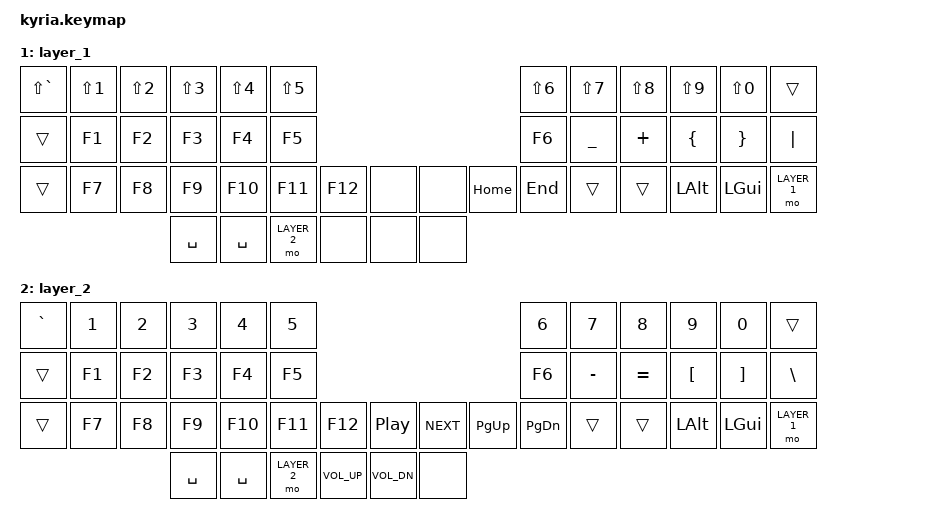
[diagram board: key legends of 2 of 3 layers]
/*
 * Copyright (c) 2020 The ZMK Contributors
 *
 * SPDX-License-Identifier: MIT
 */

#include <behaviors.dtsi>
#include <dt-bindings/zmk/keys.h>

// Layers

#define DEFAULT 0
#define LAYER_1 1
#define LAYER_2 2

/ {
    keymap {
        compatible = "zmk,keymap";

        default_layer {
            // ---------------------------------------------------------------------------------------------------------------------------------
            // |  TAB  |  Q  |  W  |  E   |  R   |  T   |                                              |  Y   |  U    |  I    |  O   |   P   | BSPC |
            // |  CTRL |  A  |  S  |  D   |  F   |  G   |                                              |  H   |  J    |  K    |  L   |   ;   |   '  |
            // | SHIFT |  Z  |  X  |  C   |  V   |  B   |  SPACE  | L SHIFT |      | L SHIFT |  SPACE  |  N   |  M    |  ,    |  .   |   /   | Hold-SHIFT, Tap-RET |
            //                     |  ESC | LALT | GUI  | LAYER_1 |  SPACE  |      |  SPACE  | LAYER_2 |      |       |       |

            bindings = <
&kp TAB    &kp Q  &kp W  &kp E    &kp R     &kp T                                                     &kp Y              &kp U  &kp I      &kp O    &kp P     &kp BSPC
&kp LCTRL  &kp A  &kp S  &kp D    &kp F     &kp G                                                     &kp H              &kp J  &kp K      &kp L    &kp SEMI  &kp SQT
&kp LSHFT  &kp Z  &kp X  &kp C    &kp V     &kp B     &kp SPACE    &kp LSHFT  &kp LSHFT  &kp SPACE    &kp N              &kp M  &kp COMMA  &kp DOT  &kp FSLH  &lt RSHIFT RET
                         &kp ESC  &kp LALT  &kp LGUI  &mo LAYER_1  &kp SPACE  &kp SPACE  &mo LAYER_2  &kp RIGHT_COMMAND  &none  &none
            >;

            sensor-bindings = <&inc_dec_kp C_VOL_UP C_VOL_DN &inc_dec_kp PG_UP PG_DN>;
        };

        layer_1 {
            // ---------------------------------------------------------------------------------------------------------------------------------
            // |  ~         |  !  |  @  |  #      |   $  |  %   |                                              |  ^   |  &  |  *  |  (   |   )   | def:BSPC |
            // | def:CTRL   | F1  | F2  |  F3     |  F4  |  F5  |                                              |  F6  |  _  |  +  |  {   |   }   |     |    |
            // | def:SHIFT  | F7  | F8  |  F9     |  F10 |  F11 |  F12    |         |      |         | SPACE   |      |     |     | Home |  End  | def:Hold-SHIFT, Tap-RET |
            //                          | def:ESC | LALT | GUI  | LAYER_1 |  SPACE  |      |  SPACE  | LAYER_2 |      |     |     |

            bindings = <
&kp LS(GRAVE)  &kp LS(N1)  &kp LS(N2)  &kp LS(N3)  &kp LS(N4)  &kp LS(N5)                                    &kp LS(N6)  &kp LS(N7)  &kp LS(N8)  &kp LS(N9)  &kp LS(N0)  &trans
&trans         &kp F1      &kp F2      &kp F3      &kp F4      &kp F5                                        &kp F6      &kp UNDER   &kp PLUS    &kp LBRC    &kp RBRC    &kp PIPE
&trans         &kp F7      &kp F8      &kp F9      &kp F10     &kp F11      &kp F12  &none  &none  &kp HOME  &kp END     &trans      &trans      &kp LALT    &kp LGUI    &mo LAYER_1
                                       &kp SPACE   &kp SPACE   &mo LAYER_2  &none    &none  &none
            >;
        };

        layer_2 {
            // ---------------------------------------------------------------------------------------------------------------------------------
            // |  `         |  1  |  2  |  3      |   4  |  5   |                                              |     6      |      7      |  8  |  9   |   0   | def:BSPC |
            // | def:CTRL   | F1  | F2  |  F3     |  F4  |  F5  |                                              |     F6     |      -      |  =  |  [   |   ]   |     \    |
            // | def:SHIFT  | F7  | F8  |  F9     |  F10 |  F11 |  F12    |         |      |         | SPACE   | PLAY SONG  |  NEXT SONG  |     | PgUp |  PgDn | def:Hold-SHIFT, Tap-RET |
            //                          | def:ESC | LALT | GUI  | LAYER_1 |  SPACE  |      |  SPACE  | LAYER_2 | VOLUME UP  | VOLUME DOWN |     |

            bindings = <
&kp GRAVE  &kp N1  &kp N2  &kp N3     &kp N4     &kp N5                                                          &kp N6     &kp N7     &kp N8     &kp N9    &kp N0    &trans
&trans     &kp F1  &kp F2  &kp F3     &kp F4     &kp F5                                                          &kp F6     &kp MINUS  &kp EQUAL  &kp LBKT  &kp RBKT  &kp BSLH
&trans     &kp F7  &kp F8  &kp F9     &kp F10    &kp F11      &kp F12       &kp C_PP      &kp C_NEXT  &kp PG_UP  &kp PG_DN  &trans     &trans     &kp LALT  &kp LGUI  &mo LAYER_1
                           &kp SPACE  &kp SPACE  &mo LAYER_2  &kp C_VOL_UP  &kp C_VOL_DN  &none
            >;
        };
    };
};
